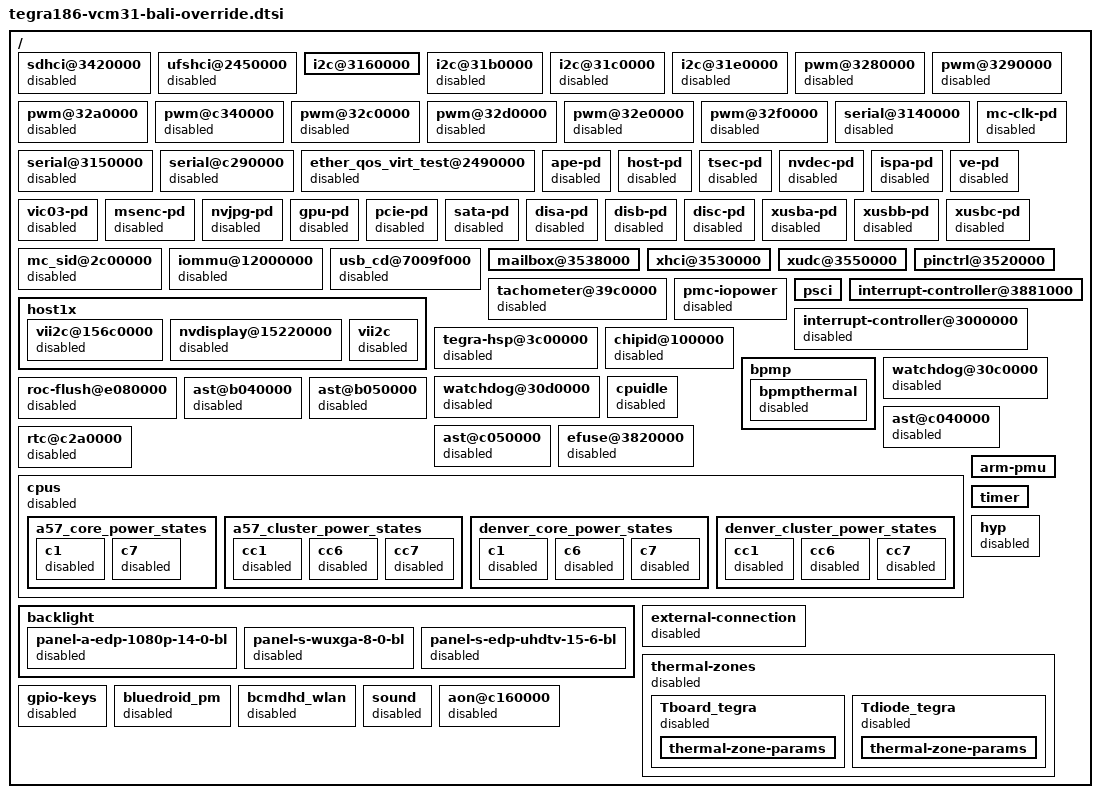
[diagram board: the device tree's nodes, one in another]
/*
 * tegra186-vcm31-bali-override.dtsi
 *
 * Copyright (c) 2015, NVIDIA CORPORATION.  All rights reserved.
 *
 * This program is free software; you can redistribute it and/or modify
 * it under the terms of the GNU General Public License as published by
 * the Free Software Foundation; version 2 of the License.
 *
 * This program is distributed in the hope that it will be useful, but WITHOUT
 * ANY WARRANTY; without even the implied warranty of MERCHANTABILITY or
 * FITNESS FOR A PARTICULAR PURPOSE.  See the GNU General Public License for
 * more details.
 */


/ {
	sdhci@3420000 {
		status = "disabled";
	};

	ufshci@2450000 {
		status = "disabled";
	};

	i2c@3160000 {
		/delete-node/ gpio@76;
		/delete-node/ gpio@75;
	};

	i2c@31b0000 {
		status = "disabled";
	};

	i2c@31c0000 {
		status = "disabled";
	};

	i2c@31e0000 {
		status = "disabled";
	};

	pwm@3280000 {
		status = "disabled";
	};

	pwm@3290000 {
		status = "disabled";
	};

	pwm@32a0000 {
		status = "disabled";
	};

	pwm@c340000 {
		status = "disabled";
	};

	pwm@32c0000 {
		status = "disabled";
	};

	pwm@32d0000 {
		status = "disabled";
	};

	pwm@32e0000 {
		status = "disabled";
	};

	pwm@32f0000 {
		status = "disabled";
	};

	serial@3140000 {
		status = "disabled";
	};

	serial@3150000 {
		status = "disabled";
	};

	serial@c290000 {
		status = "disabled";
	};

	ether_qos_virt_test@2490000 {
		status = "disabled";
	};

	mc-clk-pd {
		status = "disabled";
	};

	ape-pd {
		status = "disabled";
	};

	host-pd {
		status = "disabled";
	};

	tsec-pd {
		status = "disabled";
	};

	nvdec-pd {
		status = "disabled";
	};

	ispa-pd {
		status = "disabled";
	};

	ve-pd {
		status = "disabled";
	};

	vic03-pd {
		status = "disabled";
	};

	msenc-pd {
		status = "disabled";
	};

	nvjpg-pd {
		status = "disabled";
	};

	gpu-pd {
		status = "disabled";
	};

	pcie-pd {
		status = "disabled";
	};

	sata-pd {
		status = "disabled";
	};

	disa-pd {
		status = "disabled";
	};

	disb-pd {
		status = "disabled";
	};

	disc-pd {
		status = "disabled";
	};

	xusba-pd {
		status = "disabled";
	};

	xusbb-pd {
		status = "disabled";
	};

	xusbc-pd {
		status = "disabled";
	};


	mc_sid@2c00000 {
		status = "disabled";
	};

	iommu@12000000 {
		status = "disabled";
	};

	usb_cd@7009f000 {
		status = "disabled";
	};

	mailbox@3538000 {
		status = "okay";
	};

	xhci@3530000 {
		status = "okay";
	};

	xudc@3550000 {
		status = "okay";
	};

	pinctrl@3520000 {
		status = "okay";
	};

	tachometer@39c0000 {
		status = "disabled";
	};

	pmc-iopower {
		status = "disabled";
	};

	host1x {

		vii2c@156c0000 {
			status = "disabled";
		};

		nvdisplay@15220000 {
			status = "disabled";
		};

		vii2c {
			status = "disabled";
		};
	};

	psci {
		status = "okay";
	};

	interrupt-controller@3881000 {
		status = "okay";
	};

	interrupt-controller@3000000 {
		status = "disabled";
	};

	tegra-hsp@3c00000 {
		status = "disabled";
	};

	chipid@100000 {
		status = "disabled";
	};

	bpmp {
		status = "okay";

		bpmpthermal {
			status = "disabled";
		};
	};

	watchdog@30c0000 {
		status = "disabled";
	};

	watchdog@30d0000 {
		status = "disabled";
	};

	roc-flush@e080000 {
		status = "disabled";
	};

	cpuidle {
		status = "disabled";
	};

	ast@b040000 {
		status = "disabled";
	};

	ast@b050000 {
		status = "disabled";
	};

	ast@c040000 {
		status = "disabled";
	};

	ast@c050000 {
		status = "disabled";
	};

        efuse@3820000 {
                status = "disabled";
        };

	rtc@c2a0000 {
		status = "disabled";
	};

	cpus {
		status = "disabled";

		a57_core_power_states {

			c1 {
				status = "disabled";
			};

			c7 {
				status = "disabled";
			};
		};

		a57_cluster_power_states {

			cc1 {
				status = "disabled";
			};

			cc6 {
				status = "disabled";
			};

			cc7 {
				status = "disabled";
			};
		};

		denver_core_power_states {

			c1 {
				status = "disabled";
			};

			c6 {
				status = "disabled";
			};

			c7 {
				status = "disabled";
			};
		};

		denver_cluster_power_states {

			cc1 {
				status = "disabled";
			};

			cc6 {
				status = "disabled";
			};

			cc7 {
				status = "disabled";
			};
		};
	};

	arm-pmu {
		status = "okay";
	};

	backlight {

		panel-a-edp-1080p-14-0-bl {
			status = "disabled";
		};

		panel-s-wuxga-8-0-bl {
			status = "disabled";
		};

		panel-s-edp-uhdtv-15-6-bl {
			status = "disabled";
		};
	};

	timer {
		status = "okay";
	};

	hyp {
		status = "disabled";
	};

	external-connection {
		status = "disabled";
	};

	thermal-zones {
		status = "disabled";

		Tboard_tegra {
			status = "disabled";

			thermal-zone-params {
			};
		};

		Tdiode_tegra {
			status = "disabled";

			thermal-zone-params {
			};
		};
	};

	gpio-keys {
		status = "disabled";
	};

	bluedroid_pm {
		status = "disabled";
	};

	bcmdhd_wlan {
		status = "disabled";
	};

	sound {
		status = "disabled";
	};

	aon@c160000 {
		status = "disabled";
	};

};
